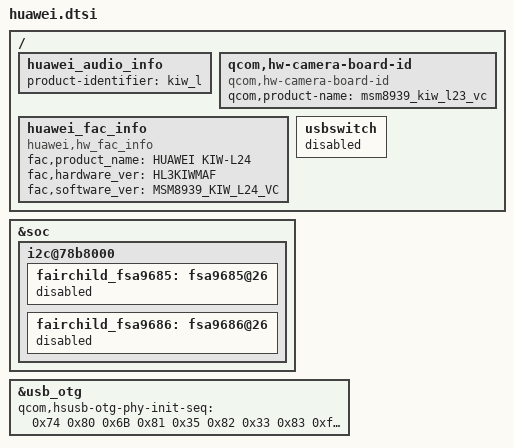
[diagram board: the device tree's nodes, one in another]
#include "../kiwi/huawei.dtsi"
#include "../kiwi/huawei-camera-vc.dtsi"
#include "../kiwi/huawei-sensors-vc.dtsi"

/ {
	huawei_audio_info {
		product-identifier = "kiw_l";
	};

	qcom,hw-camera-board-id {
		compatible = "qcom,hw-camera-board-id";
		qcom,product-name = "msm8939_kiw_l23_vc";
	};

	huawei_fac_info {
		compatible = "huawei,hw_fac_info";
		fac,product_name = "HUAWEI KIW-L24";
		fac,hardware_ver = "HL3KIWMAF";
		fac,software_ver = "MSM8939_KIW_L24_VC";
		status = "ok";
	};

	usbswitch: usbswitch {
		status = "disabled";
	};
};

&soc {
	i2c@78b8000{
		fairchild_fsa9685: fsa9685@26 {
			status = "disabled";
		};

		fairchild_fsa9686: fsa9686@26 {
			status = "disabled";
		};
	};
};

&usb_otg {
	qcom,hsusb-otg-phy-init-seq =
		<0x74 0x80 0x6B 0x81 0x35 0x82 0x33 0x83 0xffffffff>;
};
